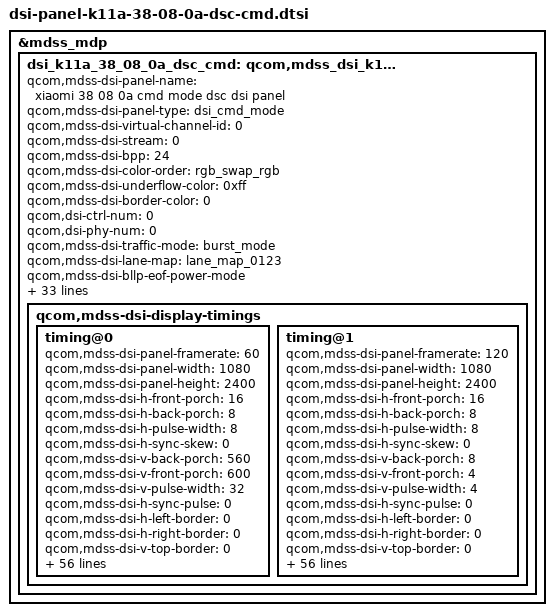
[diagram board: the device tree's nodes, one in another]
&mdss_mdp {
	dsi_k11a_38_08_0a_dsc_cmd: qcom,mdss_dsi_k11a_38_08_0a_dsc_cmd {
		qcom,mdss-dsi-panel-name = "xiaomi 38 08 0a cmd mode dsc dsi panel";
		qcom,mdss-dsi-panel-type = "dsi_cmd_mode";
		qcom,mdss-dsi-virtual-channel-id = <0>;
		qcom,mdss-dsi-stream = <0>;
		qcom,mdss-dsi-bpp = <24>;
		qcom,mdss-dsi-color-order = "rgb_swap_rgb";
		qcom,mdss-dsi-underflow-color = <0xff>;
		qcom,mdss-dsi-border-color = <0>;
		qcom,dsi-ctrl-num = <0>;
		qcom,dsi-phy-num = <0>;
		qcom,mdss-dsi-traffic-mode = "burst_mode";
		qcom,mdss-dsi-lane-map = "lane_map_0123";
		qcom,mdss-dsi-bllp-eof-power-mode;
		qcom,mdss-dsi-bllp-power-mode;
		qcom,mdss-dsi-lane-0-state;
		qcom,mdss-dsi-lane-1-state;
		qcom,mdss-dsi-lane-2-state;
		qcom,mdss-dsi-lane-3-state;
		qcom,mdss-dsi-dma-trigger = "trigger_sw";
		qcom,mdss-dsi-mdp-trigger = "none";
		qcom,mdss-dsi-reset-sequence = <0 10>, <1 10>;
		qcom,mdss-pan-physical-width-dimension = <695>;
		qcom,mdss-pan-physical-height-dimension = <1546>;
		qcom,mdss-dsi-te-pin-select = <1>;
		qcom,mdss-dsi-wr-mem-start = <0x2c>;
		qcom,mdss-dsi-wr-mem-continue = <0x3c>;
		qcom,mdss-dsi-te-dcs-command = <1>;
		qcom,mdss-dsi-te-check-enable;
		qcom,mdss-dsi-te-using-te-pin;
		qcom,mdss-dsi-tx-eot-append;
		qcom,mdss-dsi-lp11-init;
		qcom,mdss-dsi-panel-hdr-enabled;
		qcom,mdss-dsi-panel-hdr-color-primaries = <14500 15500 32000 17000 15500 30000 8000 3000>;
		qcom,mdss-dsi-panel-peak-brightness = <4200000>;
		qcom,mdss-dsi-panel-blackness-level = <3230>;
		qcom,bl-update-flag = "delay_until_first_frame";
		qcom,mdss-dsi-display-timings {
			timing@0{
				qcom,mdss-dsi-panel-framerate = <60>;
				qcom,mdss-dsi-panel-width = <1080>;
				qcom,mdss-dsi-panel-height = <2400>;
				qcom,mdss-dsi-h-front-porch = <16>;
				qcom,mdss-dsi-h-back-porch = <8>;
				qcom,mdss-dsi-h-pulse-width = <8>;
				qcom,mdss-dsi-h-sync-skew = <0>;
				qcom,mdss-dsi-v-back-porch = <560>;
				qcom,mdss-dsi-v-front-porch = <600>;
				qcom,mdss-dsi-v-pulse-width = <32>;
				qcom,mdss-dsi-h-sync-pulse = <0>;
				qcom,mdss-dsi-h-left-border = <0>;
				qcom,mdss-dsi-h-right-border = <0>;
				qcom,mdss-dsi-v-top-border = <0>;
				qcom,mdss-dsi-v-bottom-border = <0>;
				qcom,mdss-dsi-panel-clockrate = <1100000000>;
				qcom,mdss-dsi-panel-jitter = <5 1>;
				qcom,mdss-mdp-transfer-time-us = <14000>;
				qcom,mdss-dsi-on-command = [05 01 00 00 0a 00 02 11 00 39 01 00 00 00 00 02 35 00 39 01 00 00 00 00 02 9d 01 39 01 00 00 00 00 81 9e 11 00 00 89 30 80 09 60 04 38 00 08 02 1c 02 1c 02 00 02 0e 00 20 00 bb 00 07 00 0c 0d b7 0c b7 18 00 10 f0 03 0c 20 00 06 0b 0b 33 0e 1c 2a 38 46 54 62 69 70 77 79 7b 7d 7e 01 02 01 00 09 40 09 be 19 fc 19 fa 19 f8 1a 38 1a 78 1a b6 2a f6 2b 34 2b 74 3b 74 6b f4 00 00 00 00 00 00 00 00 00 00 00 00 00 00 00 00 00 00 00 00 00 00 00 00 00 00 00 00 00 00 00 00 00 00 00 00 00 00 00 00 39 00 00 00 00 00 05 2a 00 00 04 37 39 01 00 00 00 00 05 2b 00 00 09 5f 39 01 00 00 00 00 03 f0 5a 5a 39 00 00 00 00 00 02 b0 01 39 01 00 00 00 00 02 b7 4f 39 01 00 00 00 00 03 f0 a5 a5 39 01 00 00 00 00 03 f0 5a 5a 39 00 00 00 00 00 02 b0 02 39 00 00 00 00 00 05 ec 00 c0 c3 43 39 00 00 00 00 00 02 b0 0d 39 00 00 00 00 00 02 ec 19 39 00 00 00 00 00 02 b0 06 39 01 00 00 00 00 02 e4 d0 39 01 00 00 00 00 03 f0 a5 a5 39 01 00 00 00 00 03 f0 5a 5a 39 00 00 00 00 00 02 b0 36 39 00 00 00 00 00 02 d3 0f 39 01 00 00 00 00 02 f7 03 39 01 00 00 00 00 03 f0 a5 a5 39 01 00 00 00 00 03 f0 5a 5a 39 01 00 00 00 00 03 fc 5a 5a 39 00 00 00 00 00 02 b0 01 39 00 00 00 00 00 04 e4 a6 75 a3 39 01 00 00 00 00 0f e9 11 75 a6 75 a3 8d 06 20 8c a2 4e 00 32 32 39 01 00 00 00 00 03 fc a5 a5 39 01 00 00 00 00 03 f0 a5 a5 39 01 00 00 00 00 03 f0 5a 5a 39 00 00 00 00 00 04 df 83 00 10 39 00 00 00 00 00 02 b0 01 39 01 00 00 00 00 02 e6 01 39 01 00 00 00 00 03 f0 a5 a5 39 00 00 00 00 00 03 f0 5a 5a 39 00 00 00 00 00 02 b0 08 39 00 00 00 00 00 02 d4 05 39 01 00 00 00 00 03 f0 a5 a5 39 01 00 00 00 00 03 f0 5a 5a 39 01 00 00 00 00 03 fc 5a 5a 39 00 00 00 00 00 02 b0 16 39 01 00 00 00 00 02 d1 2e 39 01 00 00 00 00 03 fc a5 a5 39 01 00 00 5a 00 03 f0 a5 a5 39 01 00 00 00 00 03 f0 5a 5a 39 00 00 00 00 00 02 b0 06 39 00 00 00 00 00 02 b7 20 39 00 00 00 00 00 02 b0 05 39 01 00 00 00 00 02 b7 93 39 01 00 00 00 00 03 f0 a5 a5 39 01 00 00 00 00 02 53 20 39 01 00 00 00 00 03 51 00 00 05 01 00 00 00 00 02 29 00 39 01 00 00 00 00 02 60 00];
				qcom,mdss-dsi-off-command = [05 01 00 00 14 00 02 28 00 39 01 00 00 00 00 02 53 20 05 01 00 00 78 00 02 10 00];
				qcom,mdss-dsi-on-command-state = "dsi_lp_mode";
				qcom,mdss-dsi-off-command-state = "dsi_lp_mode";
				qcom,mdss-dsi-timing-switch-command = [39 00 00 00 00 00 02 60 00 39 00 00 00 00 00 03 f0 5a 5a 39 00 00 00 00 00 03 fc 5a 5a 39 00 00 00 00 00 02 b0 16 39 00 00 00 00 00 02 d1 2e 39 00 00 00 00 00 03 fc a5 a5 39 01 00 00 0c 00 03 f0 a5 a5];
				qcom,mdss-dsi-timing-switch-command-state = "dsi_lp_mode";
				qcom,mdss-dsi-nolp-command = [39 01 00 00 00 00 03 f0 5a 5a 39 00 00 00 00 00 02 b0 0a 39 00 00 00 00 00 02 ee 06 39 00 00 00 00 00 02 b0 0b 39 00 00 00 00 00 03 d8 59 70 39 00 00 00 00 00 02 60 00 39 00 00 00 00 00 03 fc 5a 5a 39 00 00 00 00 00 02 b0 16 39 00 00 00 00 00 02 d1 2e 39 00 00 00 00 00 03 fc a5 a5 39 01 00 00 00 00 02 53 28 39 01 00 00 11 00 03 f0 a5 a5];
				qcom,mdss-dsi-nolp-command-state = "dsi_lp_mode";
				qcom,compression-mode = "dsc";
				qcom,mdss-dsc-slice-height = <8>;
				qcom,mdss-dsc-slice-width = <540>;
				qcom,mdss-dsc-slice-per-pkt = <2>;
				qcom,mdss-dsc-bit-per-component = <8>;
				qcom,mdss-dsc-bit-per-pixel = <8>;
				qcom,mdss-dsc-block-prediction-enable;
			};
			timing@1{
				qcom,mdss-dsi-panel-framerate = <120>;
				qcom,mdss-dsi-panel-width = <1080>;
				qcom,mdss-dsi-panel-height = <2400>;
				qcom,mdss-dsi-h-front-porch = <16>;
				qcom,mdss-dsi-h-back-porch = <8>;
				qcom,mdss-dsi-h-pulse-width = <8>;
				qcom,mdss-dsi-h-sync-skew = <0>;
				qcom,mdss-dsi-v-back-porch = <8>;
				qcom,mdss-dsi-v-front-porch = <4>;
				qcom,mdss-dsi-v-pulse-width = <4>;
				qcom,mdss-dsi-h-sync-pulse = <0>;
				qcom,mdss-dsi-h-left-border = <0>;
				qcom,mdss-dsi-h-right-border = <0>;
				qcom,mdss-dsi-v-top-border = <0>;
				qcom,mdss-dsi-v-bottom-border = <0>;
				qcom,mdss-dsi-panel-clockrate = <1100000000>;
				qcom,mdss-dsi-panel-jitter = <5 1>;
				qcom,mdss-mdp-transfer-time-us = <7000>;
				qcom,mdss-dsi-on-command = [05 01 00 00 0a 00 02 11 00 39 01 00 00 00 00 02 35 00 39 01 00 00 00 00 02 9d 01 39 01 00 00 00 00 81 9e 11 00 00 89 30 80 09 60 04 38 00 08 02 1c 02 1c 02 00 02 0e 00 20 00 bb 00 07 00 0c 0d b7 0c b7 18 00 10 f0 03 0c 20 00 06 0b 0b 33 0e 1c 2a 38 46 54 62 69 70 77 79 7b 7d 7e 01 02 01 00 09 40 09 be 19 fc 19 fa 19 f8 1a 38 1a 78 1a b6 2a f6 2b 34 2b 74 3b 74 6b f4 00 00 00 00 00 00 00 00 00 00 00 00 00 00 00 00 00 00 00 00 00 00 00 00 00 00 00 00 00 00 00 00 00 00 00 00 00 00 00 00 39 00 00 00 00 00 05 2a 00 00 04 37 39 01 00 00 00 00 05 2b 00 00 09 5f 39 01 00 00 00 00 03 f0 5a 5a 39 00 00 00 00 00 02 b0 01 39 01 00 00 00 00 02 b7 4f 39 01 00 00 00 00 03 f0 a5 a5 39 01 00 00 00 00 03 f0 5a 5a 39 00 00 00 00 00 02 b0 02 39 00 00 00 00 00 05 ec 00 c0 c3 43 39 00 00 00 00 00 02 b0 0d 39 00 00 00 00 00 02 ec 19 39 00 00 00 00 00 02 b0 06 39 01 00 00 00 00 02 e4 d0 39 01 00 00 00 00 03 f0 a5 a5 39 01 00 00 00 00 03 f0 5a 5a 39 00 00 00 00 00 02 b0 36 39 00 00 00 00 00 02 d3 0f 39 01 00 00 00 00 02 f7 03 39 01 00 00 00 00 03 f0 a5 a5 39 01 00 00 00 00 03 f0 5a 5a 39 01 00 00 00 00 03 fc 5a 5a 39 00 00 00 00 00 02 b0 01 39 00 00 00 00 00 04 e4 a6 75 a3 39 01 00 00 00 00 0f e9 11 75 a6 75 a3 8d 06 20 8c a2 4e 00 32 32 39 01 00 00 00 00 03 fc a5 a5 39 01 00 00 00 00 03 f0 a5 a5 39 01 00 00 00 00 03 f0 5a 5a 39 00 00 00 00 00 04 df 83 00 10 39 00 00 00 00 00 02 b0 01 39 01 00 00 00 00 02 e6 01 39 01 00 00 00 00 03 f0 a5 a5 39 00 00 00 00 00 03 f0 5a 5a 39 00 00 00 00 00 02 b0 08 39 00 00 00 00 00 02 d4 05 39 01 00 00 00 00 03 f0 a5 a5 39 01 00 00 00 00 03 f0 5a 5a 39 01 00 00 00 00 03 fc 5a 5a 39 00 00 00 00 00 02 b0 16 39 01 00 00 00 00 02 d1 2e 39 01 00 00 00 00 03 fc a5 a5 39 01 00 00 5a 00 03 f0 a5 a5 39 01 00 00 00 00 03 f0 5a 5a 39 00 00 00 00 00 02 b0 06 39 00 00 00 00 00 02 b7 20 39 00 00 00 00 00 02 b0 05 39 01 00 00 00 00 02 b7 93 39 01 00 00 00 00 03 f0 a5 a5 39 00 00 00 00 00 02 53 20 39 01 00 00 00 00 03 51 00 00 05 01 00 00 00 00 02 29 00 39 01 00 00 00 00 02 60 10];
				qcom,mdss-dsi-off-command = [05 01 00 00 14 00 02 28 00 39 01 00 00 00 00 02 53 20 05 01 00 00 78 00 02 10 00];
				qcom,mdss-dsi-on-command-state = "dsi_lp_mode";
				qcom,mdss-dsi-off-command-state = "dsi_lp_mode";
				qcom,mdss-dsi-timing-switch-command = [39 00 00 00 00 00 02 60 10 39 00 00 00 00 00 03 f0 5a 5a 39 00 00 00 00 00 03 fc 5a 5a 39 00 00 00 00 00 02 b0 16 39 00 00 00 00 00 02 d1 2e 39 00 00 00 00 00 03 fc a5 a5 39 01 00 00 00 00 03 f0 a5 a5];
				qcom,mdss-dsi-timing-switch-command-state = "dsi_lp_mode";
				qcom,mdss-dsi-nolp-command = [39 01 00 00 00 00 03 f0 5a 5a 39 00 00 00 00 00 02 b0 0a 39 00 00 00 00 00 02 ee 06 39 00 00 00 00 00 02 b0 0b 39 00 00 00 00 00 03 d8 59 70 39 00 00 00 00 00 02 60 10 39 00 00 00 00 00 03 fc 5a 5a 39 00 00 00 00 00 02 b0 16 39 00 00 00 00 00 02 d1 2e 39 00 00 00 00 00 03 fc a5 a5 39 01 00 00 00 00 02 53 28 39 01 00 00 09 00 03 f0 a5 a5];
				qcom,mdss-dsi-nolp-command-state = "dsi_lp_mode";
				qcom,compression-mode = "dsc";
				qcom,mdss-dsc-slice-height = <8>;
				qcom,mdss-dsc-slice-width = <540>;
				qcom,mdss-dsc-slice-per-pkt = <2>;
				qcom,mdss-dsc-bit-per-component = <8>;
				qcom,mdss-dsc-bit-per-pixel = <8>;
				qcom,mdss-dsc-block-prediction-enable;
			};
		};
	};
};

&dsi_k11a_38_08_0a_dsc_cmd {
	mi,mdss-dsi-bl-dcs-big-endian-type;
	mi,feature-enabled;
	mi,mdss-dsi-panel-hbm-51-ctrl-flag;
	mi,mdss-dsi-panel-hbm-off-51-index = <1>;
	mi,esd-err-irq-gpio = <&tlmm 51 0x2001>;
	mi,mdss-panel-on-dimming-delay = <120>;
	mi,mdss-dsi-panel-hbm-brightness = <1>;
	mi,mdss-dsi-panel-dc-threshold = <440>;
	mi,mdss-dsi-panel-max-brightness-clone = <8191>;
	qcom,mdss-dsi-display-timings {
		timing@0{
			mi,mdss-dsi-dimmingon-command = [39 01 00 00 00 00 02 53 28];
			mi,mdss-dsi-dimmingon-command-state = "dsi_hs_mode";
			mi,mdss-dsi-dimmingoff-command = [39 01 00 00 00 00 02 53 20];
			mi,mdss-dsi-dimmingoff-command-state = "dsi_hs_mode";
			mi,mdss-dsi-hbm-on-command = [39 01 00 00 00 00 02 53 e8 39 01 00 00 00 00 03 51 00 00];
			mi,mdss-dsi-hbm-off-command = [39 01 00 00 00 00 02 53 28 39 01 00 00 00 00 03 51 07 ff];
			mi,mdss-dsi-hbm-on-command-state = "dsi_lp_mode";
			mi,mdss-dsi-hbm-off-command-state = "dsi_lp_mode";
			mi,mdss-dsi-doze-hbm-command = [05 01 00 00 00 00 02 28 00 39 00 00 00 00 00 03 f0 5a 5a 39 00 00 00 00 00 02 60 00 39 00 00 00 00 00 03 fc 5a 5a 39 00 00 00 00 00 02 b0 16 39 00 00 00 00 00 02 d1 2e 39 00 00 00 00 00 03 fc a5 a5 39 00 00 00 00 00 02 b0 0b 39 00 00 00 00 00 03 d8 50 00 39 00 00 00 00 00 02 53 22 39 01 00 00 22 00 03 f0 a5 a5 05 01 00 00 00 00 02 29 00];
			mi,mdss-dsi-doze-lbm-command = [05 01 00 00 00 00 02 28 00 39 00 00 00 00 00 03 f0 5a 5a 39 00 00 00 00 00 02 60 00 39 00 00 00 00 00 03 fc 5a 5a 39 00 00 00 00 00 02 b0 16 39 00 00 00 00 00 02 d1 2e 39 00 00 00 00 00 03 fc a5 a5 39 00 00 00 00 00 02 b0 0b 39 00 00 00 00 00 03 d8 50 00 39 00 00 00 00 00 02 53 23 39 01 00 00 22 00 03 f0 a5 a5 05 01 00 00 00 00 02 29 00];
			mi,mdss-dsi-doze-hbm-command-state = "dsi_lp_mode";
			mi,mdss-dsi-doze-lbm-command-state = "dsi_lp_mode";
			mi,mdss-dsi-flat-on-command = [39 00 00 00 00 00 03 f0 5a 5a 39 00 00 00 00 00 03 c2 2d 27 39 00 00 00 00 00 02 f7 03 39 01 00 00 09 00 03 f0 a5 a5];
			mi,mdss-dsi-flat-off-command = [39 00 00 00 00 00 03 f0 5a 5a 39 00 00 00 00 00 03 c2 2d 07 39 00 00 00 00 00 02 f7 03 39 01 00 00 09 00 03 f0 a5 a5];
			mi,mdss-dsi-flat-on-command-state = "dsi_lp_mode";
			mi,mdss-dsi-flat-off-command-state = "dsi_lp_mode";
			mi,mdss-dsi-crc-off-command = [39 01 00 00 00 00 02 81 00 39 00 00 00 00 00 03 f0 5a 5a 39 00 00 00 00 00 02 b1 01 39 01 00 00 00 00 03 f0 a5 a5];
			mi,mdss-dsi-crc-off-command-state = "dsi_hs_mode";
		};
		timing@1{
			mi,mdss-dsi-dimmingon-command = [39 01 00 00 00 00 02 53 28];
			mi,mdss-dsi-dimmingon-command-state = "dsi_hs_mode";
			mi,mdss-dsi-dimmingoff-command = [39 01 00 00 00 00 02 53 20];
			mi,mdss-dsi-dimmingoff-command-state = "dsi_hs_mode";
			mi,mdss-dsi-hbm-on-command = [39 01 00 00 00 00 02 53 e8 39 01 00 00 00 00 03 51 00 00];
			mi,mdss-dsi-hbm-off-command = [39 01 00 00 00 00 02 53 28 39 01 00 00 00 00 03 51 07 ff];
			mi,mdss-dsi-hbm-on-command-state = "dsi_lp_mode";
			mi,mdss-dsi-hbm-off-command-state = "dsi_lp_mode";
			mi,mdss-dsi-doze-hbm-command = [05 01 00 00 00 00 02 28 00 39 00 00 00 00 00 03 f0 5a 5a 39 00 00 00 00 00 02 60 00 39 00 00 00 00 00 03 fc 5a 5a 39 00 00 00 00 00 02 b0 16 39 00 00 00 00 00 02 d1 2e 39 00 00 00 00 00 03 fc a5 a5 39 00 00 00 00 00 02 b0 0b 39 00 00 00 00 00 03 d8 50 00 39 00 00 00 00 00 02 53 22 39 01 00 00 22 00 03 f0 a5 a5 05 01 00 00 00 00 02 29 00];
			mi,mdss-dsi-doze-lbm-command = [05 01 00 00 00 00 02 28 00 39 00 00 00 00 00 03 f0 5a 5a 39 00 00 00 00 00 02 60 00 39 00 00 00 00 00 03 fc 5a 5a 39 00 00 00 00 00 02 b0 16 39 00 00 00 00 00 02 d1 2e 39 00 00 00 00 00 03 fc a5 a5 39 00 00 00 00 00 02 b0 0b 39 00 00 00 00 00 03 d8 50 00 39 00 00 00 00 00 02 53 23 39 01 00 00 22 00 03 f0 a5 a5 05 01 00 00 00 00 02 29 00];
			mi,mdss-dsi-doze-hbm-command-state = "dsi_lp_mode";
			mi,mdss-dsi-doze-lbm-command-state = "dsi_lp_mode";
			mi,mdss-dsi-flat-on-command = [39 00 00 00 00 00 03 f0 5a 5a 39 00 00 00 00 00 03 c2 2d 27 39 00 00 00 00 00 02 f7 03 39 01 00 00 09 00 03 f0 a5 a5];
			mi,mdss-dsi-flat-off-command = [39 00 00 00 00 00 03 f0 5a 5a 39 00 00 00 00 00 03 c2 2d 07 39 00 00 00 00 00 02 f7 03 39 01 00 00 09 00 03 f0 a5 a5];
			mi,mdss-dsi-flat-on-command-state = "dsi_lp_mode";
			mi,mdss-dsi-flat-off-command-state = "dsi_lp_mode";
			mi,mdss-dsi-crc-off-command = [39 01 00 00 00 00 02 81 00 39 00 00 00 00 00 03 f0 5a 5a 39 00 00 00 00 00 02 b1 01 39 01 00 00 00 00 03 f0 a5 a5];
			mi,mdss-dsi-crc-off-command-state = "dsi_hs_mode";
		};
	};
};
